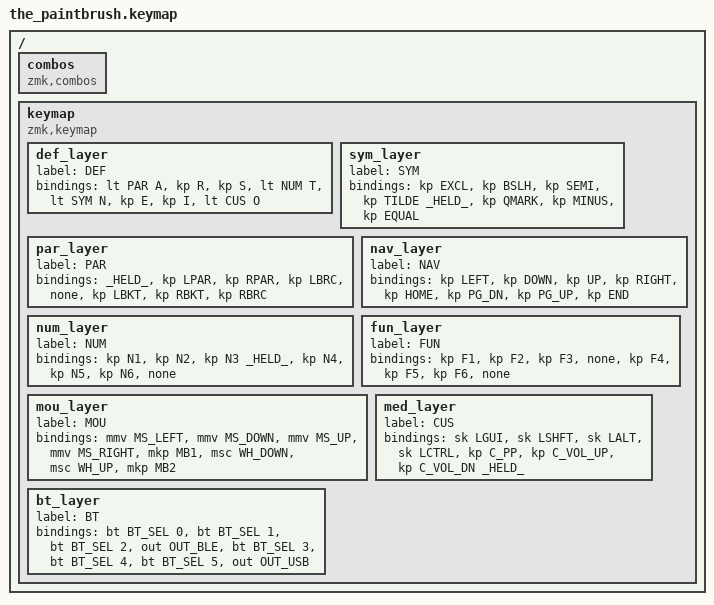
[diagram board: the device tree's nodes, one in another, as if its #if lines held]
/*
 * Copyright (c) 2021 Mike "KemoNine" Crosson
 *
 * SPDX-License-Identifier: MIT
 */

#include <behaviors.dtsi>
#include <dt-bindings/zmk/keys.h>
#include <dt-bindings/zmk/bt.h>
#include <dt-bindings/zmk/ext_power.h>
#include <dt-bindings/zmk/mouse.h>
#include <dt-bindings/zmk/outputs.h>

#define DEF 0
#define SYM 1
#define PAR 2
#define NAV 3
#define NUM 5
#define FUN 5
#define MOU 6
#define CUS 7
#define BT  8

#ifdef KEYMAP_DISPLAY
    // Ensure that custom keys are undefined so they display as labels
    #define _HELD_  &held
#else
    #define _HELD_  &none
#endif

#include "mouse.dtsi"

/ {
    combos {
        compatible = "zmk,combos";
        #include "combos_ardux.dtsi"
    };

    keymap {
        compatible = "zmk,keymap";

        def_layer {
            label = "DEF";
            bindings = <
// ╭─────────────┬─────────────┬─────────────┬─────────────╮
     &lt PAR A     &kp R         &kp S         &lt NUM T
// ├─────────────┼─────────────┼─────────────┼─────────────┼
     &lt SYM N     &kp E         &kp I         &lt CUS O     
// ╰─────────────┴─────────────┴─────────────┴─────────────╯
            >;
        };

        sym_layer {
            label = "SYM";
            bindings = <
// ╭─────────────┬─────────────┬─────────────┬─────────────╮
     &kp EXCL      &kp BSLH      &kp SEMI      &kp TILDE        
// ├─────────────┼─────────────┼─────────────┼─────────────┼
     _HELD_        &kp QMARK     &kp MINUS     &kp EQUAL        
// ╰─────────────┴─────────────┴─────────────┴─────────────╯
            >;
        };

        par_layer {
            label = "PAR";
            bindings = <
// ╭─────────────┬─────────────┬─────────────┬─────────────╮
     _HELD_        &kp LPAR      &kp RPAR      &kp LBRC
// ├─────────────┼─────────────┼─────────────┼─────────────┼
     &none         &kp LBKT      &kp RBKT      &kp RBRC
// ╰─────────────┴─────────────┴─────────────┴─────────────╯
            >;
        };

        nav_layer {
            label = "NAV";
            bindings = <
// ╭─────────────┬─────────────┬─────────────┬─────────────╮
     &kp LEFT      &kp DOWN      &kp UP        &kp RIGHT
// ├─────────────┼─────────────┼─────────────┼─────────────┼
     &kp HOME      &kp PG_DN     &kp PG_UP     &kp END
// ╰─────────────┴─────────────┴─────────────┴─────────────╯
            >;
        };

        num_layer {
            label = "NUM";
            bindings = <
// ╭─────────────┬─────────────┬─────────────┬─────────────╮
     &kp N1        &kp N2        &kp N3        _HELD_
// ├─────────────┼─────────────┼─────────────┼─────────────┼
     &kp N4        &kp N5        &kp N6        &none
// ╰─────────────┴─────────────┴─────────────┴─────────────╯
            >;
        };

        fun_layer {
            label = "FUN";
            bindings = <
// ╭─────────────┬─────────────┬─────────────┬─────────────╮
     &kp F1        &kp F2        &kp F3        &none
// ├─────────────┼─────────────┼─────────────┼─────────────┼
     &kp F4        &kp F5        &kp F6        &none
// ╰─────────────┴─────────────┴─────────────┴─────────────╯
            >;
        };

        mou_layer {
            label = "MOU";
            bindings = <
// ╭─────────────┬─────────────┬─────────────┬─────────────╮
     &mmv MS_LEFT  &mmv MS_DOWN  &mmv MS_UP    &mmv MS_RIGHT
// ├─────────────┼─────────────┼─────────────┼─────────────┼
     &mkp MB1      &msc WH_DOWN  &msc WH_UP    &mkp MB2
// ╰─────────────┴─────────────┴─────────────┴─────────────╯
            >;
        };        

        med_layer {
            label = "CUS";
            bindings = <
// ╭─────────────┬─────────────┬─────────────┬─────────────╮
     &sk LGUI      &sk LSHFT     &sk LALT      &sk LCTRL
// ├─────────────┼─────────────┼─────────────┼─────────────┼
     &kp C_PP      &kp C_VOL_UP  &kp C_VOL_DN  _HELD_
// ╰─────────────┴─────────────┴─────────────┴─────────────╯
            >;
        };

        bt_layer {
            label = "BT";
            bindings = <
// ╭─────────────┬─────────────┬─────────────┬─────────────╮
     &bt BT_SEL 0  &bt BT_SEL 1  &bt BT_SEL 2  &out OUT_BLE
// ├─────────────┼─────────────┼─────────────┼─────────────┼
     &bt BT_SEL 3  &bt BT_SEL 4  &bt BT_SEL 5  &out OUT_USB
// ╰─────────────┴─────────────┴─────────────┴─────────────╯
            >;
        };
    };
};
